AUTOSAR XML (schema 00048)
package /ComponentTypes
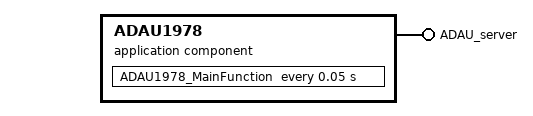
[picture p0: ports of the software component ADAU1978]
  application sw component type ADAU1978
    provide port ADAU_server: provided-com-specs=[{operation=StateToDeInit, queue-length=1}, {operation=StateToInit, queue-length=1}], provided-interface=ADAU_server
    behavior ADAU1978_InternalBehavior: port-api-option{enable-take-address=true, error-handling=NO-TRANSFORMER-ERROR-HANDLING, indirect-api=false, port=ADAU_server}
      init event ADAU1978_InitEvent: start-on-event=ADAU1978_Init
      timing event TMT_ADAU1978_MainFunction: start-on-event=ADAU1978_MainFunction, period=0.05
      operation invoked event OIT_ADAU_server_StateToDeInit_ADAU_server_StateToDeInit: start-on-event=ADAU_StateToDeInit, operation=ADAU_server.StateToDeInit
      operation invoked event OIT_ADAU_server_StateToInit_ADAU_server_StateToInit: start-on-event=ADAU_StateToInit, operation=ADAU_server.StateToInit
      4 x runnable:
        ADAU1978_Init
        ADAU1978_MainFunction
        ADAU_StateToDeInit
        ADAU_StateToInit
  swc implementation ADAU1978_Implementation: behavior=ADAU1978_InternalBehavior
